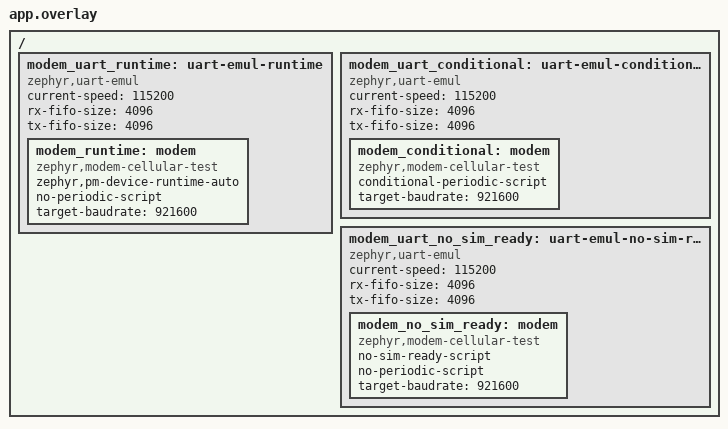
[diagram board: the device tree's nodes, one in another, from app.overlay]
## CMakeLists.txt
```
# Copyright (c) 2026 Embeint Inc
# SPDX-License-Identifier: Apache-2.0

cmake_minimum_required(VERSION 3.28.0)
# The test driver binding is shared with the original driver's tests
list(APPEND DTS_ROOT ${CMAKE_CURRENT_SOURCE_DIR}/../cellular_common)
find_package(Zephyr REQUIRED HINTS $ENV{ZEPHYR_BASE})
project(modem_cellular_v2_test)

set(common ${CMAKE_CURRENT_SOURCE_DIR}/../cellular_common)
target_sources(app PRIVATE
  ${common}/driver/modem_cellular_test.c
  ${common}/src/stubs.c
  ${common}/src/test_helpers.c
  src/apn.c
  src/board_init.c
  src/core.c
  src/gpio.c
  src/lte_rf.c
  src/modem_info.c
  src/periodic.c
  src/ppp.c
  src/registration.c
  src/script_errors.c
  src/sim.c
  src/suspend.c
)
target_include_directories(app PRIVATE
  ${common}/driver
  ${common}/src
  ${ZEPHYR_BASE}/subsys/modem
)
```

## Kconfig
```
# Copyright (c) 2026 Embeint Inc
# SPDX-License-Identifier: Apache-2.0

rsource "../cellular_common/Kconfig"

source "Kconfig.zephyr"
```

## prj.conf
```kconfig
# Copyright (c) 2026 Embeint Inc
# SPDX-License-Identifier: Apache-2.0

CONFIG_ZTEST=y

CONFIG_SERIAL=y
CONFIG_EMUL=y
CONFIG_UART_EMUL=y
CONFIG_GPIO=y

CONFIG_MODEM=y
CONFIG_MODEM_MODULES=y
CONFIG_MODEM_CELLULAR=y
CONFIG_MODEM_CELLULAR_V2=y
CONFIG_MODEM_CELLULAR_HW_DEPENDENCIES=n
CONFIG_MODEM_CHAT=y
CONFIG_MODEM_PIPELINK=y

CONFIG_NETWORKING=y
CONFIG_NET_L2_PPP=y
CONFIG_NET_MGMT=y
CONFIG_NET_MGMT_EVENT=y
CONFIG_PM_DEVICE=y
CONFIG_PM_DEVICE_RUNTIME=y
# The PPP L2 reports the link dead, as with the hardware dependencies
CONFIG_NET_L2_PPP_MGMT=y
# The PPP device reports why the modem failed
CONFIG_NET_MGMT_EVENT_INFO=y

CONFIG_ETH_NATIVE_TAP=n

CONFIG_LOG=y
CONFIG_LOG_MODE_IMMEDIATE=y
CONFIG_MODEM_LOG_LEVEL_INF=y

CONFIG_MODEM_CELLULAR_APN=""
CONFIG_MODEM_CELLULAR_RECOVERY_BACKOFF_MS=100
CONFIG_MODEM_CELLULAR_MAX_RECOVERIES=3
CONFIG_MODEM_CELLULAR_PERIODIC_SCRIPT_MS=500
CONFIG_MODEM_CELLULAR_SIM_TIMEOUT_MS=1000

CONFIG_MAIN_STACK_SIZE=4096
CONFIG_SYSTEM_WORKQUEUE_STACK_SIZE=4096
CONFIG_ZTEST_STACK_SIZE=4096
```

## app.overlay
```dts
/*
 * Copyright (c) 2026 Embeint Inc
 *
 * SPDX-License-Identifier: Apache-2.0
 */

#include "../cellular_common/modems.dtsi"

/* Modems only the MODEM_CELLULAR_V2 suites use */
/ {
	modem_uart_runtime: uart-emul-runtime {
		compatible = "zephyr,uart-emul";
		current-speed = <115200>;
		rx-fifo-size = <4096>;
		tx-fifo-size = <4096>;
		status = "okay";

		/* Only powered while something holds a runtime PM reference on it */
		modem_runtime: modem {
			compatible = "zephyr,modem-cellular-test";
			zephyr,pm-device-runtime-auto;
			/* Keeps the PPP tests to the commands they drive */
			no-periodic-script;
			target-baudrate = <921600>;
			status = "okay";
		};
	};

	modem_uart_conditional: uart-emul-conditional {
		compatible = "zephyr,uart-emul";
		current-speed = <115200>;
		rx-fifo-size = <4096>;
		tx-fifo-size = <4096>;
		status = "okay";

		modem_conditional: modem {
			compatible = "zephyr,modem-cellular-test";
			conditional-periodic-script;
			target-baudrate = <921600>;
			status = "okay";
		};
	};

	modem_uart_no_sim_ready: uart-emul-no-sim-ready {
		compatible = "zephyr,uart-emul";
		current-speed = <115200>;
		rx-fifo-size = <4096>;
		tx-fifo-size = <4096>;
		status = "okay";

		modem_no_sim_ready: modem {
			compatible = "zephyr,modem-cellular-test";
			no-sim-ready-script;
			no-periodic-script;
			target-baudrate = <921600>;
			status = "okay";
		};
	};
};
```

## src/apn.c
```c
/*
 * Copyright (c) 2026 Embeint Inc
 *
 * SPDX-License-Identifier: Apache-2.0
 */

/*
 * MODEM_CELLULAR_V2 configures the data context with the APN before each LTE RF enable, and
 * rejects LTE RF requests while no APN is available.
 */

#include "test_helpers.h"

#include <zephyr/device.h>
#include <zephyr/drivers/cellular.h>
#include <zephyr/drivers/modem/modem_cellular.h>
#include <modem_cellular_test.h>
#include <zephyr/ztest.h>

BUILD_ASSERT(IS_ENABLED(CONFIG_MODEM_CELLULAR_V2));

#define OTHER_APN     "other"
#define OTHER_APN_CMD "AT+CGDCONT=1,\"IP\",\"" OTHER_APN "\""

/* Without a periodic script, so that only the commands under test are sent */
static const struct device *const modem = DEVICE_DT_GET(DT_NODELABEL(modem_no_periodic));
static const struct device *const modem_default_pdp =
	DEVICE_DT_GET(DT_NODELABEL(modem_default_pdp));

static void boot_to_ready(const struct device *dev)
{
	modem_restart(dev);
	advance_to(dev, BOOT_AT_READY);
}

/* Answer @p cmd with OK, or ERROR unless @p success, and check the driver read it */
static void answer(const char *cmd, bool success)
{
	expect_line(TEST_BACKEND_PIPE_DLCI1, cmd);
	if (success) {
		ok(TEST_BACKEND_PIPE_DLCI1);
	} else {
		respond_error(TEST_BACKEND_PIPE_DLCI1);
	}
	expect_read(TEST_BACKEND_PIPE_DLCI1);
}

ZTEST(modem_cellular_v2_apn, test_request_rejected_without_apn)
{
	boot_to_ready(modem);

	zassert_equal(-ENODATA, modem_cellular_lte_rf_request(modem));
	expect_no_line(K_MSEC(100));
	/* A rejected request is not held */
	zassert_equal(-EALREADY, modem_cellular_lte_rf_release(modem));
}

/* An APN set once a request was rejected lets the next one through */
ZTEST(modem_cellular_v2_apn, test_request_after_apn_set)
{
	boot_to_ready(modem);
	zassert_equal(-ENODATA, modem_cellular_lte_rf_request(modem));

	zassert_ok(cellular_set_apn(modem, TEST_APN));
	zassert_ok(modem_cellular_lte_rf_request(modem));
	answer(TEST_APN_CMD, true);
	answer(MODEM_CELLULAR_TEST_LTE_RF_ENABLE_CMD, true);
	expect_no_line(K_MSEC(100));
}

/* An empty APN counts as set, and is configured for the network to select the default APN */
ZTEST(modem_cellular_v2_apn, test_empty_apn)
{
	boot_to_ready(modem);
	zassert_equal(-ENODATA, modem_cellular_lte_rf_request(modem));

	zassert_ok(cellular_set_apn(modem, ""));
	zassert_equal(-EALREADY, cellular_set_apn(modem, ""));
	zassert_ok(modem_cellular_lte_rf_request(modem));
	answer("AT+CGDCONT=1,\"IP\",\"\"", true);
	answer(MODEM_CELLULAR_TEST_LTE_RF_ENABLE_CMD, true);
	expect_no_line(K_MSEC(100));
}

ZTEST(modem_cellular_v2_apn, test_set_apn_validated)
{
	char too_long[MODEM_CELLULAR_DATA_APN_LEN + 1];

	memset(too_long, 'a', sizeof(too_long) - 1);
	too_long[sizeof(too_long) - 1] = '\0';

	zassert_equal(-EINVAL, cellular_set_apn(modem, NULL));
	zassert_equal(-EINVAL, cellular_set_apn(modem, too_long));
	zassert_ok(cellular_set_apn(modem, TEST_APN));
	zassert_equal(-EALREADY, cellular_set_apn(modem, TEST_APN));
}

/* The APN cannot change under a held request, and the new one is used on the next enable */
ZTEST(modem_cellular_v2_apn, test_change_while_requested)
{
	boot_to_ready(modem);
	zassert_ok(cellular_set_apn(modem, TEST_APN));
	zassert_ok(modem_cellular_lte_rf_request(modem));
	answer(TEST_APN_CMD, true);
	answer(MODEM_CELLULAR_TEST_LTE_RF_ENABLE_CMD, true);

	zassert_equal(-EBUSY, cellular_set_apn(modem, OTHER_APN));

	zassert_ok(modem_cellular_lte_rf_release(modem));
	answer(MODEM_CELLULAR_TEST_LTE_RF_DISABLE_CMD, true);
	zassert_ok(cellular_set_apn(modem, OTHER_APN));

	zassert_ok(modem_cellular_lte_rf_request(modem));
	answer(OTHER_APN_CMD, true);
	answer(MODEM_CELLULAR_TEST_LTE_RF_ENABLE_CMD, true);
}

/* Release, set the APN and request again before the driver gets to run */
static void change_apn_at_once(void)
{
	zassert_ok(modem_cellular_lte_rf_release(modem));
	zassert_ok(cellular_set_apn(modem, OTHER_APN));
	zassert_ok(modem_cellular_lte_rf_request(modem));
}

/* An APN changed between a release and the next request is configured, however quickly the
 * request follows
 */
ZTEST(modem_cellular_v2_apn, test_change_between_release_and_request)
{
	boot_to_ready(modem);
	zassert_ok(cellular_set_apn(modem, TEST_APN));
	zassert_ok(modem_cellular_lte_rf_request(modem));
	answer(TEST_APN_CMD, true);
	answer(MODEM_CELLULAR_TEST_LTE_RF_ENABLE_CMD, true);

	change_apn_at_once();
	answer(MODEM_CELLULAR_TEST_LTE_RF_DISABLE_CMD, true);
	answer(OTHER_APN_CMD, true);
	answer(MODEM_CELLULAR_TEST_LTE_RF_ENABLE_CMD, true);
	expect_no_line(K_MSEC(100));
}

/* As test_change_between_release_and_request, while the old APN is being configured */
ZTEST(modem_cellular_v2_apn, test_change_during_configuration)
{
	boot_to_ready(modem);
	zassert_ok(cellular_set_apn(modem, TEST_APN));
	zassert_ok(modem_cellular_lte_rf_request(modem));
	expect_line(TEST_BACKEND_PIPE_DLCI1, TEST_APN_CMD);

	change_apn_at_once();
	ok(TEST_BACKEND_PIPE_DLCI1);
	answer(OTHER_APN_CMD, true);
	answer(MODEM_CELLULAR_TEST_LTE_RF_ENABLE_CMD, true);
	expect_no_line(K_MSEC(100));
}

/* As test_change_between_release_and_request, while the LTE RF is being enabled */
ZTEST(modem_cellular_v2_apn, test_change_during_enable)
{
	boot_to_ready(modem);
	zassert_ok(cellular_set_apn(modem, TEST_APN));
	zassert_ok(modem_cellular_lte_rf_request(modem));
	answer(TEST_APN_CMD, true);
	expect_line(TEST_BACKEND_PIPE_DLCI1, MODEM_CELLULAR_TEST_LTE_RF_ENABLE_CMD);

	change_apn_at_once();
	ok(TEST_BACKEND_PIPE_DLCI1);
	answer(MODEM_CELLULAR_TEST_LTE_RF_DISABLE_CMD, true);
	answer(OTHER_APN_CMD, true);
	answer(MODEM_CELLULAR_TEST_LTE_RF_ENABLE_CMD, true);
	expect_no_line(K_MSEC(100));
}

/* A failed configuration is retried after the LTE RF retry interval, the LTE RF staying off */
ZTEST(modem_cellular_v2_apn, test_failure_retried)
{
	int64_t start;

	boot_to_ready(modem);
	zassert_ok(cellular_set_apn(modem, TEST_APN));
	zassert_ok(modem_cellular_lte_rf_request(modem));
	expect_line(TEST_BACKEND_PIPE_DLCI1, TEST_APN_CMD);

	start = k_uptime_get();
	respond_error(TEST_BACKEND_PIPE_DLCI1);
	expect_no_line(K_MSEC(CONFIG_MODEM_CELLULAR_LTE_RF_RETRY_MS / 2));
	answer(TEST_APN_CMD, true);
	zassert_true(k_uptime_delta(&start) >= CONFIG_MODEM_CELLULAR_LTE_RF_RETRY_MS,
		     "retried before the LTE RF retry interval");
	answer(MODEM_CELLULAR_TEST_LTE_RF_ENABLE_CMD, true);
}

ZTEST(modem_cellular_v2_apn, test_failure_released)
{
	boot_to_ready(modem);
	zassert_ok(cellular_set_apn(modem, TEST_APN));
	zassert_ok(modem_cellular_lte_rf_request(modem));
	answer(TEST_APN_CMD, false);

	zassert_ok(modem_cellular_lte_rf_release(modem));
	expect_no_line(K_MSEC(CONFIG_MODEM_CELLULAR_LTE_RF_RETRY_MS * 2));
}

/* Releasing while the APN is configured leaves the LTE RF off */
ZTEST(modem_cellular_v2_apn, test_released_during_configuration)
{
	boot_to_ready(modem);
	zassert_ok(cellular_set_apn(modem, TEST_APN));
	zassert_ok(modem_cellular_lte_rf_request(modem));
	expect_line(TEST_BACKEND_PIPE_DLCI1, TEST_APN_CMD);

	zassert_ok(modem_cellular_lte_rf_release(modem));
	ok(TEST_BACKEND_PIPE_DLCI1);
	expect_read(TEST_BACKEND_PIPE_DLCI1);
	expect_no_line(K_MSEC(100));
}

/* The APN is configured again on each enable, as the modem may have lost it */
ZTEST(modem_cellular_v2_apn, test_configured_on_each_enable)
{
	boot_to_ready(modem);
	zassert_ok(cellular_set_apn(modem, TEST_APN));
	zassert_ok(modem_cellular_lte_rf_request(modem));
	answer(TEST_APN_CMD, true);
	answer(MODEM_CELLULAR_TEST_LTE_RF_ENABLE_CMD, true);
	suspend_with_lte_rf_and_shutdown(modem);

	zassert_ok(modem_cellular_pm_action(modem, PM_DEVICE_ACTION_RESUME), "resume failed");
	advance_to(modem, BOOT_AT_READY);
	answer(TEST_APN_CMD, true);
	answer(MODEM_CELLULAR_TEST_LTE_RF_ENABLE_CMD, true);
}

/* The default PDP context is left to the modem, so no APN is needed or configured */
ZTEST(modem_cellular_v2_apn, test_default_pdp_context)
{
	boot_to_ready(modem_default_pdp);

	zassert_ok(modem_cellular_lte_rf_request(modem_default_pdp));
	answer(MODEM_CELLULAR_TEST_LTE_RF_ENABLE_CMD, true);
	expect_no_line(K_MSEC(100));
}

ZTEST_SUITE(modem_cellular_v2_apn, NULL, modem_test_setup, modem_test_before, modem_test_after,
	    NULL);
```

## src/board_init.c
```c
/*
 * Copyright (c) 2026 Embeint Inc
 *
 * SPDX-License-Identifier: Apache-2.0
 */

#include "test_helpers.h"

#include <zephyr/device.h>
#include <zephyr/drivers/cellular.h>
#include <zephyr/drivers/modem/modem_cellular.h>
#include <modem_cellular_test.h>
#include <zephyr/modem/chat.h>
#include <zephyr/ztest.h>

#define BOARD_INIT_CMD_1 "AT+BOARDINIT=1"
#define BOARD_INIT_CMD_2 "AT+BOARDINIT=2"

static const struct device *const modem_board_init =
	DEVICE_DT_GET(DT_NODELABEL(modem_board_init));

MODEM_CHAT_MATCH_DEFINE(board_init_ok_match, "OK", "", NULL);
MODEM_CHAT_MATCHES_DEFINE(board_init_abort_matches, MODEM_CHAT_MATCH("ERROR", "", NULL));
MODEM_CHAT_SCRIPT_CMDS_DEFINE(board_init_cmds,
			      MODEM_CHAT_SCRIPT_CMD_RESP(BOARD_INIT_CMD_1, board_init_ok_match),
			      MODEM_CHAT_SCRIPT_CMD_RESP(BOARD_INIT_CMD_2, board_init_ok_match));
/* The driver replaces the callback with its own */
MODEM_CHAT_SCRIPT_DEFINE(board_init_script, board_init_cmds, board_init_abort_matches, NULL, 1);

MODEM_CELLULAR_BOARD_INIT_DEFINE(DT_NODELABEL(modem_board_init), &board_init_script);

/* Boot until the board init script is about to start, after the DLCI setup and SIM check */
static void boot_to_board_init(void)
{
	modem_restart(modem_board_init);
	advance_to(modem_board_init, BOOT_AT_READY);
}

/* Answer the whole board init script */
static void run_board_init(void)
{
	expect_line(TEST_BACKEND_PIPE_DLCI1, BOARD_INIT_CMD_1);
	ok(TEST_BACKEND_PIPE_DLCI1);
	expect_line(TEST_BACKEND_PIPE_DLCI1, BOARD_INIT_CMD_2);
	ok(TEST_BACKEND_PIPE_DLCI1);
}

/* With the script done, the driver moves on to the APN */
static void expect_apn(void)
{
	expect_read(TEST_BACKEND_PIPE_DLCI1);
	expect_no_line(K_MSEC(100));
	zassert_ok(cellular_set_apn(modem_board_init, TEST_APN));
	zassert_ok(modem_cellular_lte_rf_request(modem_board_init));
	expect_line(TEST_BACKEND_PIPE_DLCI1, TEST_APN_CMD);
}

/* The script runs on DLCI1 once the SIM is checked, before the APN is configured */
ZTEST(modem_cellular_board_init, test_runs_before_apn)
{
	boot_to_board_init();
	run_board_init();
	expect_apn();
}

static K_SEM_DEFINE(modem_ready, 0, K_SEM_MAX_LIMIT);

static void modem_ready_handler(const struct device *dev, enum cellular_event event,
				const void *payload, void *user_data)
{
	ARG_UNUSED(dev);
	ARG_UNUSED(event);
	ARG_UNUSED(payload);
	ARG_UNUSED(user_data);

	k_sem_give(&modem_ready);
}

/* The modem is only reported ready once the script has run */
ZTEST(modem_cellular_board_init, test_ready_after_script)
{
	k_sem_reset(&modem_ready);
	zassert_ok(cellular_set_callback(modem_board_init, CELLULAR_EVENT_MODEM_READY,
					 modem_ready_handler, NULL));

	boot_to_board_init();
	expect_line(TEST_BACKEND_PIPE_DLCI1, BOARD_INIT_CMD_1);
	ok(TEST_BACKEND_PIPE_DLCI1);
	expect_line(TEST_BACKEND_PIPE_DLCI1, BOARD_INIT_CMD_2);
	zassert_equal(0, k_sem_count_get(&modem_ready), "ready reported during the script");

	ok(TEST_BACKEND_PIPE_DLCI1);
	zassert_ok(k_sem_take(&modem_ready, K_SECONDS(1)), "ready not reported");

	zassert_ok(cellular_set_callback(modem_board_init, 0, NULL, NULL));
}

/* A failed script is run again from the start after the periodic interval */
ZTEST(modem_cellular_board_init, test_retried)
{
	int64_t start;

	boot_to_board_init();
	expect_line(TEST_BACKEND_PIPE_DLCI1, BOARD_INIT_CMD_1);
	ok(TEST_BACKEND_PIPE_DLCI1);
	expect_line(TEST_BACKEND_PIPE_DLCI1, BOARD_INIT_CMD_2);

	start = k_uptime_get();
	respond_error(TEST_BACKEND_PIPE_DLCI1);
	expect_no_line(K_MSEC(CONFIG_MODEM_CELLULAR_PERIODIC_SCRIPT_MS / 2));
	run_board_init();
	zassert_true(k_uptime_delta(&start) >= CONFIG_MODEM_CELLULAR_PERIODIC_SCRIPT_MS,
		     "retried before the periodic interval");
	expect_apn();
}

static atomic_t modem_failed;

static void modem_failed_handler(const struct device *dev, enum cellular_event event,
				 const void *payload, void *user_data)
{
	ARG_UNUSED(dev);
	ARG_UNUSED(event);
	ARG_UNUSED(payload);
	ARG_UNUSED(user_data);

	atomic_inc(&modem_failed);
}

/* Spending the failure budget powers the modem down */
ZTEST(modem_cellular_board_init, test_failures_shut_down)
{
	boot_to_board_init();
	atomic_clear(&modem_failed);
	zassert_ok(cellular_set_callback(modem_board_init, CELLULAR_EVENT_MODEM_FAILED,
					 modem_failed_handler, NULL));
	for (int i = 0; i < CONFIG_MODEM_CELLULAR_MAX_SCRIPT_FAILURES; i++) {
		expect_line(TEST_BACKEND_PIPE_DLCI1, BOARD_INIT_CMD_1);
		respond_error(TEST_BACKEND_PIPE_DLCI1);
	}

	expect_line(TEST_BACKEND_PIPE_UART, MODEM_CELLULAR_TEST_SHUTDOWN_CMD);
	ok(TEST_BACKEND_PIPE_UART);
	expect_state(modem_board_init, TEST_BACKEND_STATE_OFF);
	expect_no_line(K_MSEC(CONFIG_MODEM_CELLULAR_PERIODIC_SCRIPT_MS * 2));
	zassert_equal(1, atomic_get(&modem_failed), "modem failure not reported");
}

/* Failures before a suspend do not count against the script after the resume */
ZTEST(modem_cellular_board_init, test_failures_forgotten_on_resume)
{
	boot_to_board_init();
	expect_line(TEST_BACKEND_PIPE_DLCI1, BOARD_INIT_CMD_1);
	respond_error(TEST_BACKEND_PIPE_DLCI1);
	suspend_and_shutdown(modem_board_init);

	zassert_ok(modem_cellular_pm_action(modem_board_init, PM_DEVICE_ACTION_RESUME));
	advance_to(modem_board_init, BOOT_AT_READY);
	for (int i = 0; i < CONFIG_MODEM_CELLULAR_MAX_SCRIPT_FAILURES - 1; i++) {
		expect_line(TEST_BACKEND_PIPE_DLCI1, BOARD_INIT_CMD_1);
		respond_error(TEST_BACKEND_PIPE_DLCI1);
	}
	run_board_init();
	expect_apn();
}

ZTEST(modem_cellular_board_init, test_suspend)
{
	boot_to_board_init();
	expect_line(TEST_BACKEND_PIPE_DLCI1, BOARD_INIT_CMD_1);
	suspend_and_shutdown(modem_board_init);
}

ZTEST_SUITE(modem_cellular_board_init, NULL, modem_test_setup, modem_test_before,
	    modem_test_after, NULL);
```

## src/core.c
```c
/*
 * Copyright (c) 2026 Embeint Inc
 *
 * SPDX-License-Identifier: Apache-2.0
 */

/*
 * MODEM_CELLULAR_V2 brings the modem up until the CMUX connects and it has set up the AT
 * command channel on DLCI1, and no further. The PPP channel on DLCI2 is then handed out
 * through a pipelink, as are the user pipes.
 */

#include "test_helpers.h"

#include <zephyr/device.h>
#include <zephyr/drivers/cellular.h>
#include <zephyr/drivers/gpio/gpio_emul.h>
#include <zephyr/drivers/modem/modem_cellular.h>
#include <modem_cellular_test.h>
#include <modem_workqueue.h>
#include <zephyr/modem/pipe.h>
#include <zephyr/modem/pipelink.h>
#include <zephyr/ztest.h>

#include <string.h>

BUILD_ASSERT(IS_ENABLED(CONFIG_MODEM_CELLULAR_V2));

#define TARGET_BAUDRATE          DT_PROP(DT_ALIAS(modem), target_baudrate)
#define BAUDRATE_UPDATE_DELAY_MS DT_PROP(DT_ALIAS(modem), baudrate_update_delay_ms)

static const struct device *const modem = DEVICE_DT_GET(DT_ALIAS(modem));
static const struct device *const modem_slow = DEVICE_DT_GET(DT_NODELABEL(modem_slow));
static const struct device *const modem_no_power = DEVICE_DT_GET(DT_NODELABEL(modem_no_power));
static const struct device *const modem_no_shutdown =
	DEVICE_DT_GET(DT_NODELABEL(modem_no_shutdown));
static const struct device *const modem_no_dlci_setup =
	DEVICE_DT_GET(DT_NODELABEL(modem_no_dlci_setup));

MODEM_PIPELINK_DT_DECLARE(DT_ALIAS(modem), MODEM_CELLULAR_PIPELINK_PPP);
MODEM_PIPELINK_DT_DECLARE(DT_ALIAS(modem), user_pipe_0);
MODEM_PIPELINK_DT_DECLARE(DT_ALIAS(modem), user_pipe_1);
MODEM_PIPELINK_DT_DECLARE(DT_NODELABEL(modem_no_dlci_setup), MODEM_CELLULAR_PIPELINK_PPP);

/* Every pipelink of the modem, and the DLCI it carries */
static const struct {
	struct modem_pipelink *link;
	enum test_backend_pipe_id pipe;
} pipelinks[] = {
	{MODEM_PIPELINK_DT_GET(DT_ALIAS(modem), MODEM_CELLULAR_PIPELINK_PPP),
	 TEST_BACKEND_PIPE_DLCI2},
	{MODEM_PIPELINK_DT_GET(DT_ALIAS(modem), user_pipe_0), TEST_BACKEND_PIPE_USER3},
	{MODEM_PIPELINK_DT_GET(DT_ALIAS(modem), user_pipe_1), TEST_BACKEND_PIPE_USER4},
};

static void expect_pipelinks_connected(bool connected)
{
	for (size_t i = 0; i < ARRAY_SIZE(pipelinks); i++) {
		zassert_equal(connected, modem_pipelink_is_connected(pipelinks[i].link),
			      "pipelink %zu connected is %d", i, !connected);
	}
}

/* The driver keeps the AT command channel, and brings nothing else up */
ZTEST(modem_cellular_v2_core, test_stops_when_at_ready)
{
	modem_restart(modem);
	advance_to(modem, BOOT_AT_READY);
	expect_pipelinks_connected(true);
	zassert_true(test_backend_pipe_is_open(TEST_BACKEND_PIPE_DLCI1), "DLCI1 not opened");
	zassert_false(test_backend_pipe_is_open(TEST_BACKEND_PIPE_DLCI2), "DLCI2 opened");

	/* The driver chat reads the AT command channel */
	registered(TEST_BACKEND_PIPE_DLCI1);
	expect_read(TEST_BACKEND_PIPE_DLCI1);

	/* Nothing until the periodic script is due */
	expect_no_line(K_MSEC(CONFIG_MODEM_CELLULAR_PERIODIC_SCRIPT_MS / 2));
	zassert_equal(TEST_BACKEND_STATE_CMUX, test_backend_state(modem));
}

/* The other channels are only handed out once DLCI1 is set up and the SIM checked */
ZTEST(modem_cellular_v2_core, test_pipelinks_wait_for_dlci_setup)
{
	modem_restart(modem);
	advance_to(modem, BOOT_CMUX_PENDING);
	expect_pipelinks_connected(false);

	test_backend_cmux_connect_finish(true);
	expect_line(TEST_BACKEND_PIPE_DLCI1, MODEM_CELLULAR_TEST_DLCI_SETUP_CMD);
	expect_pipelinks_connected(false);

	ok(TEST_BACKEND_PIPE_DLCI1);
	answer_reports();
	expect_line(TEST_BACKEND_PIPE_DLCI1, TEST_CPIN_CMD);
	expect_pipelinks_connected(false);

	respond_cpin("READY");
	expect_line(TEST_BACKEND_PIPE_DLCI1, MODEM_CELLULAR_TEST_SIM_READY_CMD);
	expect_pipelinks_connected(false);

	ok(TEST_BACKEND_PIPE_DLCI1);
	expect_read(TEST_BACKEND_PIPE_DLCI1);
	flush_driver_events();
	expect_pipelinks_connected(true);
}

/* A failed DLCI setup is not critical, the channel still takes commands */
ZTEST(modem_cellular_v2_core, test_dlci_setup_failure)
{
	modem_restart(modem);
	advance_to(modem, BOOT_DLCI1_SETUP);

	respond_error(TEST_BACKEND_PIPE_DLCI1);
	answer_reports();
	expect_line(TEST_BACKEND_PIPE_DLCI1, TEST_CPIN_CMD);
	respond_cpin("READY");
	expect_line(TEST_BACKEND_PIPE_DLCI1, MODEM_CELLULAR_TEST_SIM_READY_CMD);
	ok(TEST_BACKEND_PIPE_DLCI1);
	expect_read(TEST_BACKEND_PIPE_DLCI1);
	flush_driver_events();
	expect_pipelinks_connected(true);
	expect_no_line(K_MSEC(100));
}

/* Reports the modem cannot enable are logged, and the modem brought up regardless */
ZTEST(modem_cellular_v2_core, test_reports_failure)
{
	modem_restart(modem);
	advance_to(modem, BOOT_REPORTS);

	respond_error(TEST_BACKEND_PIPE_DLCI1);
	expect_line(TEST_BACKEND_PIPE_DLCI1, TEST_CEREG_CMD);
	respond_error(TEST_BACKEND_PIPE_DLCI1);
	expect_line(TEST_BACKEND_PIPE_DLCI1, TEST_CGEREP_CMD);
	test_backend_respond(TEST_BACKEND_PIPE_DLCI1, "+CME ERROR: 4\r");
	expect_line(TEST_BACKEND_PIPE_DLCI1, TEST_CPIN_CMD);
	respond_cpin("READY");
	expect_line(TEST_BACKEND_PIPE_DLCI1, MODEM_CELLULAR_TEST_SIM_READY_CMD);
	ok(TEST_BACKEND_PIPE_DLCI1);
	expect_read(TEST_BACKEND_PIPE_DLCI1);
	flush_driver_events();
	expect_pipelinks_connected(true);
}

/* Without a DLCI setup script the reports are enabled as soon as DLCI1 opens */
ZTEST(modem_cellular_v2_core, test_no_dlci_setup_script)
{
	struct modem_pipelink *ppp = MODEM_PIPELINK_DT_GET(DT_NODELABEL(modem_no_dlci_setup),
							   MODEM_CELLULAR_PIPELINK_PPP);

	modem_restart(modem_no_dlci_setup);
	advance_to(modem_no_dlci_setup, BOOT_CMUX_CONNECTED);
	answer_reports();
	expect_line(TEST_BACKEND_PIPE_DLCI1, TEST_CPIN_CMD);
	respond_cpin("READY");
	expect_line(TEST_BACKEND_PIPE_DLCI1, MODEM_CELLULAR_TEST_SIM_READY_CMD);
	ok(TEST_BACKEND_PIPE_DLCI1);
	expect_read(TEST_BACKEND_PIPE_DLCI1);
	flush_driver_events();
	zassert_true(modem_pipelink_is_connected(ppp), "PPP pipelink not connected");
	zassert_true(test_backend_pipe_is_open(TEST_BACKEND_PIPE_DLCI1), "DLCI1 not opened");
	expect_no_line(K_MSEC(100));
}

/* Suspending before DLCI1 is set up never hands out the other channels */
ZTEST(modem_cellular_v2_core, test_suspend_during_dlci_setup)
{
	modem_restart(modem);
	advance_to(modem, BOOT_DLCI1_SETUP);

	suspend_and_shutdown(modem);
	expect_pipelinks_connected(false);
}

/* Pipelinks each carry their own DLCI */
ZTEST(modem_cellular_v2_core, test_pipelinks)
{
	static const char cmd[] = "AT+USER\r";

	modem_restart(modem);
	advance_to(modem, BOOT_AT_READY);
	for (size_t i = 0; i < ARRAY_SIZE(pipelinks); i++) {
		struct modem_pipe *pipe = modem_pipelink_get_pipe(pipelinks[i].link);

		zassert_ok(modem_pipe_open(pipe, K_SECONDS(2)));
		zassert_true(test_backend_pipe_is_open(pipelinks[i].pipe));
		zassert_equal(strlen(cmd),
			      modem_pipe_transmit(pipe, (const uint8_t *)cmd, strlen(cmd)));
		expect_line(pipelinks[i].pipe, "AT+USER");
	}

	suspend_and_shutdown(modem);
	expect_pipelinks_connected(false);
}

/* Halting the driver disconnects the pipelinks, as powering down does */
ZTEST(modem_cellular_v2_core, test_pipelinks_halt)
{
	modem_restart(modem);
	advance_to(modem, BOOT_AT_READY);
	expect_pipelinks_connected(true);

	modem_cellular_ztest_halt(modem);
	expect_pipelinks_connected(false);
}

/* The modem powers up at its default baudrate, so the UART is restored first */
ZTEST(modem_cellular_v2_core, test_suspend_and_resume)
{
	modem_restart(modem);
	advance_to(modem, BOOT_AT_READY);
	zassert_equal(TARGET_BAUDRATE, uart_baudrate(modem),
		      "UART baudrate was not switched");

	suspend_and_shutdown(modem);

	zassert_ok(modem_cellular_pm_action(modem, PM_DEVICE_ACTION_RESUME), "resume failed");
	expect_line(TEST_BACKEND_PIPE_UART, MODEM_CELLULAR_TEST_SET_BAUDRATE_CMD);
	zassert_equal(modem_power_up_baudrate(modem), uart_baudrate(modem),
		      "UART baudrate was not restored on power up");
	ok(TEST_BACKEND_PIPE_UART);

	expect_line(TEST_BACKEND_PIPE_UART, MODEM_CELLULAR_TEST_INIT_CMD);
	zassert_equal(TARGET_BAUDRATE, uart_baudrate(modem),
		      "UART baudrate was not switched");
	ok(TEST_BACKEND_PIPE_UART);
	expect_line(TEST_BACKEND_PIPE_DLCI1, MODEM_CELLULAR_TEST_DLCI_SETUP_CMD);
}

static K_SEM_DEFINE(modem_ready, 0, K_SEM_MAX_LIMIT);

static void modem_ready_handler(const struct device *dev, enum cellular_event event,
				const void *payload, void *user_data)
{
	ARG_UNUSED(dev);
	ARG_UNUSED(event);
	ARG_UNUSED(payload);
	ARG_UNUSED(user_data);

	k_sem_give(&modem_ready);
}

/* Readiness is reported once per boot, and not on suspend */
ZTEST(modem_cellular_v2_core, test_ready_reported_each_boot)
{
	k_sem_reset(&modem_ready);
	zassert_ok(cellular_set_callback(modem, CELLULAR_EVENT_MODEM_READY, modem_ready_handler,
					 NULL));

	modem_restart(modem);
	advance_to(modem, BOOT_AT_READY);
	zassert_ok(k_sem_take(&modem_ready, K_SECONDS(1)), "ready not reported");

	suspend_and_shutdown(modem);
	zassert_equal(0, k_sem_count_get(&modem_ready), "ready reported on suspend");

	zassert_ok(modem_cellular_pm_action(modem, PM_DEVICE_ACTION_RESUME), "resume failed");
	advance_to(modem, BOOT_AT_READY);
	zassert_ok(k_sem_take(&modem_ready, K_SECONDS(1)), "ready not reported on resume");
	zassert_equal(0, k_sem_count_get(&modem_ready), "ready reported more than once");

	zassert_ok(cellular_set_callback(modem, 0, NULL, NULL));
}

/*
 * Without a reset or power key, recovery boots the modem again as it is, at its power up
 * baudrate, until the recovery attempts are spent.
 */
ZTEST(modem_cellular_v2_core, test_recovery_without_gpios)
{
	modem_restart(modem_no_power);
	advance_to(modem_no_power, BOOT_SET_BAUDRATE);
	ok(TEST_BACKEND_PIPE_UART);

	for (int i = 0; i < CONFIG_MODEM_CELLULAR_MAX_RECOVERIES; i++) {
		expect_line(TEST_BACKEND_PIPE_UART, MODEM_CELLULAR_TEST_INIT_CMD);
		respond_error(TEST_BACKEND_PIPE_UART);
		expect_line(TEST_BACKEND_PIPE_UART, MODEM_CELLULAR_TEST_SET_BAUDRATE_CMD);
		zassert_equal(modem_power_up_baudrate(modem_no_power),
			      uart_baudrate(modem_no_power),
			      "UART baudrate was not restored for the retry");
		ok(TEST_BACKEND_PIPE_UART);
	}

	/* Spent, so powered down rather than retried */
	expect_line(TEST_BACKEND_PIPE_UART, MODEM_CELLULAR_TEST_INIT_CMD);
	respond_error(TEST_BACKEND_PIPE_UART);
	expect_state(modem_no_power, TEST_BACKEND_STATE_OFF);
	expect_no_line(K_MSEC(CONFIG_MODEM_CELLULAR_RECOVERY_BACKOFF_MS *
			      (CONFIG_MODEM_CELLULAR_MAX_RECOVERIES + 1)));
}

ZTEST(modem_cellular_v2_core, test_uart_backend_init_failure)
{
	modem_reset_state(modem);
	test_backend_uart_init_fail_once();
	zassert_equal(-EIO, modem_cellular_init(modem));

	/* A later initialization can still succeed. */
	modem_restart(modem);
	advance_to(modem, BOOT_SET_BAUDRATE);
}

ZTEST(modem_cellular_v2_core, test_uart_open_failure_recovers)
{
	modem_restart(modem);
	advance_to(modem, BOOT_SET_BAUDRATE);
	test_backend_pipe_fail_next_open(TEST_BACKEND_PIPE_UART);
	ok(TEST_BACKEND_PIPE_UART);

	/* The failed init-script open enters recovery and starts boot again. */
	expect_line(TEST_BACKEND_PIPE_UART, MODEM_CELLULAR_TEST_SET_BAUDRATE_CMD);
}

ZTEST(modem_cellular_v2_core, test_uart_close_failure_recovers)
{
	modem_restart(modem);
	advance_to(modem, BOOT_INIT);
	test_backend_pipe_fail_next_close(TEST_BACKEND_PIPE_UART);
	ok(TEST_BACKEND_PIPE_UART);

	/* The failed close after init enters recovery and starts boot again. */
	expect_line(TEST_BACKEND_PIPE_UART, MODEM_CELLULAR_TEST_SET_BAUDRATE_CMD);
}

ZTEST(modem_cellular_v2_core, test_dlci1_open_failure_recovers)
{
	modem_restart(modem);
	advance_to(modem, BOOT_CMUX_PENDING);
	test_backend_pipe_fail_next_open(TEST_BACKEND_PIPE_DLCI1);
	test_backend_cmux_connect_finish(true);

	/* The failed command-channel open enters recovery and starts boot again. */
	expect_line(TEST_BACKEND_PIPE_UART, MODEM_CELLULAR_TEST_SET_BAUDRATE_CMD);
}

ZTEST(modem_cellular_v2_core, test_dlci1_open_timeout_recovers)
{
	modem_restart(modem);
	advance_to(modem, BOOT_CMUX_PENDING);
	test_backend_pipe_close_next_open(TEST_BACKEND_PIPE_DLCI1);
	test_backend_cmux_connect_finish(true);

	/* The CMUX reports a closed pipe after its open retries are exhausted. */
	expect_line(TEST_BACKEND_PIPE_UART, MODEM_CELLULAR_TEST_SET_BAUDRATE_CMD);
}

/* A command-channel failure remains visible after the chat has attached to DLCI1. */
ZTEST(modem_cellular_v2_core, test_dlci1_close_after_attach_recovers)
{
	modem_restart(modem_no_dlci_setup);
	advance_to(modem_no_dlci_setup, BOOT_SIM);

	test_backend_pipe_disconnect(TEST_BACKEND_PIPE_DLCI1);

	/* Recovery restarts the modem instead of waiting for a future script failure. */
	expect_line(TEST_BACKEND_PIPE_UART, MODEM_CELLULAR_TEST_SET_BAUDRATE_CMD);
}

/* The init script waits for the UART to close and reopen at the new baudrate, however long the
 * close takes
 */
ZTEST(modem_cellular_v2_core, test_baudrate_waits_for_close)
{
	modem_restart(modem);
	advance_to(modem, BOOT_SET_BAUDRATE);
	test_backend_pipe_close_hold(TEST_BACKEND_PIPE_UART);
	ok(TEST_BACKEND_PIPE_UART);
	zassert_true(test_backend_pipe_wait_for_close(TEST_BACKEND_PIPE_UART, K_SECONDS(1)),
		     "UART not closed after the set baudrate script");

	expect_no_line(K_MSEC(BAUDRATE_UPDATE_DELAY_MS + 100));
	zassert_equal(modem_power_up_baudrate(modem), uart_baudrate(modem),
		      "baudrate changed before the UART closed");

	test_backend_pipe_close_finish(TEST_BACKEND_PIPE_UART);
	expect_line(TEST_BACKEND_PIPE_UART, MODEM_CELLULAR_TEST_INIT_CMD);
	zassert_equal(TARGET_BAUDRATE, uart_baudrate(modem),
		      "init script not run at the new baudrate");
}

static K_SEM_DEFINE(workqueue_release, 0, 1);

static void workqueue_block_handler(struct k_work *work)
{
	ARG_UNUSED(work);

	(void)k_sem_take(&workqueue_release, K_FOREVER);
}

/* An open that completes after the startup time ran out, with its event queued behind the
 * timeout, does not restart the script started once the UART is reopened
 */
ZTEST(modem_cellular_v2_core, test_late_uart_open_ignored)
{
	static struct k_work block;

	modem_reset_state(modem_slow);
	test_backend_pipe_open_hold(TEST_BACKEND_PIPE_UART);
	zassert_ok(modem_cellular_init(modem_slow));
	zassert_true(test_backend_pipe_wait_for_open(TEST_BACKEND_PIPE_UART, K_SECONDS(2)),
		     "UART never opened");

	/* Hold the driver until the startup time is out, then complete the open */
	k_sem_reset(&workqueue_release);
	k_work_init(&block, workqueue_block_handler);
	zassert_equal(1, modem_work_submit(&block));
	k_msleep(DT_PROP(DT_NODELABEL(modem_slow), startup_time_ms) * 2);
	test_backend_pipe_open_finish(TEST_BACKEND_PIPE_UART);
	k_sem_give(&workqueue_release);

	/* The reopened UART reports open at once, and the second report changes nothing */
	expect_line(TEST_BACKEND_PIPE_UART, MODEM_CELLULAR_TEST_SET_BAUDRATE_CMD);
	flush_driver_events();
	zassert_true(test_backend_pipe_is_open(TEST_BACKEND_PIPE_UART),
		     "set baudrate script given up on");

	ok(TEST_BACKEND_PIPE_UART);
	expect_line(TEST_BACKEND_PIPE_UART, MODEM_CELLULAR_TEST_INIT_CMD);
}

/* Without a reset or power key, recovery takes a modem left in CMUX mode back to AT mode
 * before booting it again
 */
ZTEST(modem_cellular_v2_core, test_recovery_without_gpios_disconnects_cmux)
{
	modem_restart(modem_no_power);
	advance_to(modem_no_power, BOOT_AT_READY);

	test_backend_pipe_disconnect(TEST_BACKEND_PIPE_DLCI1);
	expect_line(TEST_BACKEND_PIPE_UART, MODEM_CELLULAR_TEST_SET_BAUDRATE_CMD);
	zassert_equal(1, test_backend_cmux_disconnects(), "CMUX not disconnected");
	ok(TEST_BACKEND_PIPE_UART);
	expect_line(TEST_BACKEND_PIPE_UART, MODEM_CELLULAR_TEST_INIT_CMD);
}

/* A fault after the CMUX connects does not reset the recovery attempts */
ZTEST(modem_cellular_v2_core, test_recovery_spent_after_cmux)
{
	modem_restart(modem_no_dlci_setup);

	for (int i = 0; i <= CONFIG_MODEM_CELLULAR_MAX_RECOVERIES; i++) {
		advance_to(modem_no_dlci_setup, BOOT_SIM);
		test_backend_pipe_disconnect(TEST_BACKEND_PIPE_DLCI1);
	}

	/* Spent, so powered down rather than retried */
	expect_state(modem_no_dlci_setup, TEST_BACKEND_STATE_OFF);
	expect_no_line(K_MSEC(CONFIG_MODEM_CELLULAR_RECOVERY_BACKOFF_MS *
			      (CONFIG_MODEM_CELLULAR_MAX_RECOVERIES + 1)));
}

static struct {
	const struct gpio_dt_spec *spec;
	struct gpio_callback cb;
	int last;
	atomic_t presses;
} power_key;

static void power_key_handler(const struct device *port, struct gpio_callback *cb,
			      gpio_port_pins_t pins)
{
	int value = gpio_emul_output_get_dt(power_key.spec);

	ARG_UNUSED(port);
	ARG_UNUSED(cb);
	ARG_UNUSED(pins);

	if ((value == 1) && (power_key.last == 0)) {
		atomic_inc(&power_key.presses);
	}
	power_key.last = value;
}

/* Count the presses of the power key of @p dev from now on */
static void power_key_monitor_start(const struct device *dev)
{
	power_key.spec = test_backend_power_gpio(dev);
	power_key.last = gpio_emul_output_get_dt(power_key.spec);
	atomic_clear(&power_key.presses);
	gpio_init_callback(&power_key.cb, power_key_handler, BIT(power_key.spec->pin));
	zassert_ok(gpio_add_callback_dt(power_key.spec, &power_key.cb));
}

static atomic_val_t power_key_monitor_stop(void)
{
	(void)gpio_remove_callback_dt(power_key.spec, &power_key.cb);
	return atomic_get(&power_key.presses);
}

/* A modem that never reached CMUX is off, so recovery presses the power key once */
ZTEST(modem_cellular_v2_core, test_recovery_powers_on_stopped_modem)
{
	modem_restart(modem);
	advance_to(modem, BOOT_RECOVERY);
	power_key_monitor_start(modem);

	expect_line(TEST_BACKEND_PIPE_UART, MODEM_CELLULAR_TEST_SET_BAUDRATE_CMD);
	zassert_equal(1, power_key_monitor_stop(), "power key not pressed once");
}

/* A fault after the CMUX connects leaves the modem running, so recovery turns it off first */
ZTEST(modem_cellular_v2_core, test_recovery_power_cycles_running_modem)
{
	modem_restart(modem_no_dlci_setup);
	advance_to(modem_no_dlci_setup, BOOT_SIM);
	power_key_monitor_start(modem_no_dlci_setup);

	test_backend_pipe_disconnect(TEST_BACKEND_PIPE_DLCI1);
	expect_line(TEST_BACKEND_PIPE_UART, MODEM_CELLULAR_TEST_SET_BAUDRATE_CMD);
	zassert_equal(2, power_key_monitor_stop(), "power key not pressed twice");
}

/* Already suspended, so a second suspend returns without touching the modem */
ZTEST(modem_cellular_v2_core, test_suspend_when_idle)
{
	modem_restart(modem);
	advance_to(modem, BOOT_AT_READY);
	suspend_and_shutdown(modem);

	start_suspend(modem);
	finish_suspend(modem);
	expect_no_line(K_MSEC(100));
}

/* Software shutdown failed, fall back to the power key */
ZTEST(modem_cellular_v2_core, test_shutdown_script_failure)
{
	modem_restart(modem_slow);
	advance_to(modem_slow, BOOT_AT_READY);

	start_suspend(modem_slow);
	expect_line(TEST_BACKEND_PIPE_UART, MODEM_CELLULAR_TEST_SHUTDOWN_CMD);
	respond_error(TEST_BACKEND_PIPE_UART);
	expect_gpio(test_backend_power_gpio(modem_slow), 1);
	expect_gpio(test_backend_power_gpio(modem_slow), 0);
	finish_suspend(modem_slow);
	expect_no_line(K_MSEC(100));
}

/* Without a power key a failed shutdown script leaves the modem as it is */
ZTEST(modem_cellular_v2_core, test_shutdown_without_power_key)
{
	modem_restart(modem_no_power);
	advance_to(modem_no_power, BOOT_AT_READY);

	start_suspend(modem_no_power);
	expect_line(TEST_BACKEND_PIPE_UART, MODEM_CELLULAR_TEST_SHUTDOWN_CMD);
	respond_error(TEST_BACKEND_PIPE_UART);
	finish_suspend(modem_no_power);
	expect_no_line(K_MSEC(100));
}

/* Without a shutdown script the modem is powered down with the power key alone */
ZTEST(modem_cellular_v2_core, test_no_shutdown_script)
{
	modem_restart(modem_no_shutdown);
	advance_to(modem_no_shutdown, BOOT_AT_READY);

	start_suspend(modem_no_shutdown);
	finish_suspend(modem_no_shutdown);
	expect_no_line(K_MSEC(100));
}

ZTEST_SUITE(modem_cellular_v2_core, NULL, modem_test_setup, modem_test_before, modem_test_after,
	    NULL);
```

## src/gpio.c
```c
/*
 * Copyright (c) 2026 Embeint Inc
 *
 * SPDX-License-Identifier: Apache-2.0
 */

#include "test_helpers.h"

#include <zephyr/device.h>
#include <zephyr/drivers/gpio/gpio_emul.h>
#include <zephyr/drivers/modem/modem_cellular.h>
#include <modem_cellular_test.h>
#include <zephyr/ztest.h>

#define AUTOSTART_STARTUP_TIME_MS DT_PROP(DT_NODELABEL(modem_autostart), startup_time_ms)

static const struct device *const modem_hold = DEVICE_DT_GET(DT_NODELABEL(modem_hold));
static const struct device *const modem_resume = DEVICE_DT_GET(DT_NODELABEL(modem_resume));
static const struct device *const modem_recovery = DEVICE_DT_GET(DT_NODELABEL(modem_recovery));
static const struct device *const modem_autostart =
	DEVICE_DT_GET(DT_NODELABEL(modem_autostart));
static const struct device *const modem_status = DEVICE_DT_GET(DT_NODELABEL(modem_status));

static const struct gpio_dt_spec status_gpio =
	GPIO_DT_SPEC_GET(DT_NODELABEL(modem_status), mdm_status_gpios);

enum gpio_role {
	GPIO_ROLE_POWER,
	GPIO_ROLE_RESET,
};

/* A level change on a monitored pin, and the state of the link when it happened */
struct gpio_edge {
	enum gpio_role role;
	int value;
	enum test_backend_state state;
};

K_MSGQ_DEFINE(gpio_edges, sizeof(struct gpio_edge), 16, 4);

static struct {
	const struct device *dev;
	struct gpio_callback cb;
	int last[2];
	bool overflow;
} monitor;

static const char *const gpio_role_names[] = {
	[GPIO_ROLE_POWER] = "power",
	[GPIO_ROLE_RESET] = "reset",
};

static void gpio_monitor_record(enum gpio_role role, const struct gpio_dt_spec *spec)
{
	struct gpio_edge edge = {
		.role = role,
		.value = gpio_emul_output_get_dt(spec),
		.state = test_backend_state(monitor.dev),
	};

	if (edge.value == monitor.last[role]) {
		return;
	}
	monitor.last[role] = edge.value;
	/* Runs on the driver's thread, so leave asserting to the test thread */
	if (k_msgq_put(&gpio_edges, &edge, K_NO_WAIT) != 0) {
		monitor.overflow = true;
	}
}

/* The emulated GPIO controller fires callbacks synchronously on output changes, so every
 * level the driver drives is seen, however short the pulse.
 */
static void gpio_monitor_handler(const struct device *port, struct gpio_callback *cb,
				 gpio_port_pins_t pins)
{
	ARG_UNUSED(port);
	ARG_UNUSED(cb);
	ARG_UNUSED(pins);

	gpio_monitor_record(GPIO_ROLE_POWER, test_backend_power_gpio(monitor.dev));
	gpio_monitor_record(GPIO_ROLE_RESET, test_backend_reset_gpio(monitor.dev));
}

static void gpio_monitor_start(const struct device *dev)
{
	const struct gpio_dt_spec *power_gpio = test_backend_power_gpio(dev);
	const struct gpio_dt_spec *reset_gpio = test_backend_reset_gpio(dev);

	/* Start every test from released lines so the first recorded edge is the driver's */
	zassert_ok(gpio_pin_configure_dt(power_gpio, GPIO_OUTPUT_INACTIVE));
	zassert_ok(gpio_pin_configure_dt(reset_gpio, GPIO_OUTPUT_INACTIVE));

	monitor.dev = dev;
	monitor.last[GPIO_ROLE_POWER] = 0;
	monitor.last[GPIO_ROLE_RESET] = 0;
	monitor.overflow = false;
	k_msgq_purge(&gpio_edges);

	gpio_init_callback(&monitor.cb, gpio_monitor_handler,
			   BIT(power_gpio->pin) | BIT(reset_gpio->pin));
	zassert_ok(gpio_add_callback_dt(reset_gpio, &monitor.cb));
}

static void gpio_monitor_stop(void)
{
	if (monitor.dev == NULL) {
		return;
	}

	(void)gpio_remove_callback_dt(test_backend_reset_gpio(monitor.dev), &monitor.cb);
	monitor.dev = NULL;
}

/* Wait for the next edge, which must be @p role going to @p value in @p state */
static void expect_edge(enum gpio_role role, int value, enum test_backend_state state)
{
	struct gpio_edge edge;

	zassert_false(monitor.overflow, "GPIO edge queue overflowed");
	zassert_ok(k_msgq_get(&gpio_edges, &edge, K_SECONDS(1)), "timed out waiting for %s=%d",
		   gpio_role_names[role], value);
	zassert_equal(role, edge.role, "%s went to %d, expected %s=%d", gpio_role_names[edge.role],
		      edge.value, gpio_role_names[role], value);
	zassert_equal(value, edge.value, "%s went to %d, expected %d", gpio_role_names[role],
		      edge.value, value);
	zassert_equal(state, edge.state, "%s went to %d in state %d, expected state %d",
		      gpio_role_names[role], value, edge.state, state);
}

/* Expect @p role to be asserted and released again, both in @p state */
static void expect_pulse(enum gpio_role role, enum test_backend_state state)
{
	expect_edge(role, 1, state);
	expect_edge(role, 0, state);
}

/* Assert that neither pin changed since the last expected edge */
static void expect_no_edge(void)
{
	struct gpio_edge edge;

	zassert_false(monitor.overflow, "GPIO edge queue overflowed");
	if (k_msgq_get(&gpio_edges, &edge, K_NO_WAIT) == 0) {
		zassert_unreachable("unexpected %s=%d in state %d", gpio_role_names[edge.role],
				    edge.value, edge.state);
	}
}

static int64_t boot_modem(const struct device *dev)
{
	int64_t start;

	modem_reset_state(dev);
	gpio_monitor_start(dev);

	start = k_uptime_get();
	zassert_ok(modem_cellular_init(dev), "failed to reinitialize %s", dev->name);
	return start;
}

ZTEST(modem_cellular_gpio, test_hold_on_suspend)
{
	boot_modem(modem_hold);

	/* Held through init, released before the power key and the UART */
	expect_edge(GPIO_ROLE_RESET, 1, TEST_BACKEND_STATE_OFF);
	expect_edge(GPIO_ROLE_RESET, 0, TEST_BACKEND_STATE_OFF);
	expect_pulse(GPIO_ROLE_POWER, TEST_BACKEND_STATE_OFF);
	expect_line(TEST_BACKEND_PIPE_UART, MODEM_CELLULAR_TEST_SET_BAUDRATE_CMD);
	expect_no_edge();

	/* Reasserted on suspend */
	zassert_ok(modem_cellular_pm_action(modem_hold, PM_DEVICE_ACTION_SUSPEND),
		   "suspend failed");
	expect_edge(GPIO_ROLE_RESET, 1, TEST_BACKEND_STATE_AT);
	expect_no_edge();

	/* Released again on resume, before the power key and the UART */
	zassert_ok(modem_cellular_pm_action(modem_hold, PM_DEVICE_ACTION_RESUME), "resume failed");
	expect_edge(GPIO_ROLE_RESET, 0, TEST_BACKEND_STATE_OFF);
	expect_pulse(GPIO_ROLE_POWER, TEST_BACKEND_STATE_OFF);
	expect_line(TEST_BACKEND_PIPE_UART, MODEM_CELLULAR_TEST_SET_BAUDRATE_CMD);
	expect_no_edge();
}

ZTEST(modem_cellular_gpio, test_toggle_on_resume)
{
	boot_modem(modem_resume);

	expect_pulse(GPIO_ROLE_RESET, TEST_BACKEND_STATE_OFF);
	expect_pulse(GPIO_ROLE_POWER, TEST_BACKEND_STATE_OFF);
	expect_line(TEST_BACKEND_PIPE_UART, MODEM_CELLULAR_TEST_SET_BAUDRATE_CMD);
	expect_no_edge();

	/* Untouched on suspend, which powers the modem off */
	zassert_ok(modem_cellular_pm_action(modem_resume, PM_DEVICE_ACTION_SUSPEND),
		   "suspend failed");
	expect_pulse(GPIO_ROLE_POWER, TEST_BACKEND_STATE_OFF);
	expect_no_edge();

	/* Pulsed again on resume, before the power key and the UART */
	zassert_ok(modem_cellular_pm_action(modem_resume, PM_DEVICE_ACTION_RESUME),
		   "resume failed");
	expect_pulse(GPIO_ROLE_RESET, TEST_BACKEND_STATE_OFF);
	expect_pulse(GPIO_ROLE_POWER, TEST_BACKEND_STATE_OFF);
	expect_line(TEST_BACKEND_PIPE_UART, MODEM_CELLULAR_TEST_SET_BAUDRATE_CMD);
	expect_no_edge();
}

ZTEST(modem_cellular_gpio, test_toggle_on_recovery)
{
	boot_modem(modem_recovery);

	/* Untouched on boot */
	expect_pulse(GPIO_ROLE_POWER, TEST_BACKEND_STATE_OFF);
	expect_line(TEST_BACKEND_PIPE_UART, MODEM_CELLULAR_TEST_SET_BAUDRATE_CMD);
	expect_no_edge();
	ok(TEST_BACKEND_PIPE_UART);

	/* Fail the init script to push the state machine into recovery */
	expect_line(TEST_BACKEND_PIPE_UART, MODEM_CELLULAR_TEST_INIT_CMD);
	respond_error(TEST_BACKEND_PIPE_UART);

	expect_pulse(GPIO_ROLE_RESET, TEST_BACKEND_STATE_AT);
	expect_pulse(GPIO_ROLE_POWER, TEST_BACKEND_STATE_AT);
	expect_line(TEST_BACKEND_PIPE_UART, MODEM_CELLULAR_TEST_SET_BAUDRATE_CMD);
	expect_no_edge();
}

ZTEST(modem_cellular_gpio, test_autostarts_ready_message)
{
	struct test_backend_line line;
	int64_t start = boot_modem(modem_autostart);

	/* No AT commands until the modem reports it is ready */
	zassert_false(test_backend_wait_for_line(&line, K_MSEC(100)), "'%s' sent before ready",
		      line.data);
	zassert_equal(TEST_BACKEND_STATE_AT, test_backend_state(modem_autostart),
		      "boot stopped in state %d", test_backend_state(modem_autostart));
	test_backend_respond(TEST_BACKEND_PIPE_UART, "Ready\r");

	expect_line(TEST_BACKEND_PIPE_UART, MODEM_CELLULAR_TEST_SET_BAUDRATE_CMD);
	zassert_true(k_uptime_delta(&start) < AUTOSTART_STARTUP_TIME_MS,
		     "ready message did not cut the startup wait short");
	expect_no_edge();
}

ZTEST(modem_cellular_gpio, test_autostarts_ready_timeout)
{
	int64_t start = boot_modem(modem_autostart);
	int64_t elapsed;

	/* Without a ready message the full startup time elapses before AT commands */
	expect_line(TEST_BACKEND_PIPE_UART, MODEM_CELLULAR_TEST_SET_BAUDRATE_CMD);
	elapsed = k_uptime_delta(&start);
	zassert_true(elapsed >= AUTOSTART_STARTUP_TIME_MS,
		     "AT commands sent %lld ms after boot, before startup time elapsed",
		     (long long)elapsed);

	/* Autostarting modems go straight to waiting for the modem to come up */
	expect_no_edge();
}

static void set_modem_status(int value)
{
	zassert_ok(gpio_pin_configure_dt(&status_gpio, GPIO_INPUT));
	zassert_ok(gpio_emul_input_set_dt(&status_gpio, value));
}

ZTEST(modem_cellular_gpio, test_status_unpowered)
{
	set_modem_status(0);
	boot_modem(modem_status);

	expect_pulse(GPIO_ROLE_POWER, TEST_BACKEND_STATE_OFF);
	expect_line(TEST_BACKEND_PIPE_UART, MODEM_CELLULAR_TEST_SET_BAUDRATE_CMD);
	expect_no_edge();
}

ZTEST(modem_cellular_gpio, test_status_powered)
{
	set_modem_status(1);
	boot_modem(modem_status);

	/* Pulsing the power key would turn the running modem off */
	advance_to(modem_status, BOOT_CMUX_CONNECTED);
	expect_no_edge();
}

ZTEST(modem_cellular_gpio, test_status_powered_unresponsive)
{
	int64_t start;

	set_modem_status(1);
	boot_modem(modem_status);

	advance_to(modem_status, BOOT_INIT);
	expect_no_edge();

	/* The status line was wrong, so power the modem on without the recovery backoff */
	start = k_uptime_get();
	respond_error(TEST_BACKEND_PIPE_UART);
	expect_edge(GPIO_ROLE_POWER, 1, TEST_BACKEND_STATE_AT);
	zassert_true(k_uptime_delta(&start) < CONFIG_MODEM_CELLULAR_RECOVERY_BACKOFF_MS,
		     "recovery was entered");
	expect_edge(GPIO_ROLE_POWER, 0, TEST_BACKEND_STATE_AT);
	expect_line(TEST_BACKEND_PIPE_UART, MODEM_CELLULAR_TEST_SET_BAUDRATE_CMD);
	zassert_equal(modem_power_up_baudrate(modem_status), uart_baudrate(modem_status),
		      "UART baudrate was not restored on power up");
	expect_no_edge();
}

/* A suspend during the init script powers the modem off, so the resume powers it on from the
 * original baudrate
 */
ZTEST(modem_cellular_gpio, test_status_suspend_from_init)
{
	set_modem_status(1);
	boot_modem(modem_status);
	advance_to(modem_status, BOOT_INIT);

	start_suspend(modem_status);
	expect_pulse(GPIO_ROLE_POWER, TEST_BACKEND_STATE_OFF);
	set_modem_status(0);
	finish_suspend(modem_status);
	expect_no_edge();

	zassert_ok(modem_cellular_pm_action(modem_status, PM_DEVICE_ACTION_RESUME));
	expect_pulse(GPIO_ROLE_POWER, TEST_BACKEND_STATE_OFF);
	expect_line(TEST_BACKEND_PIPE_UART, MODEM_CELLULAR_TEST_SET_BAUDRATE_CMD);
	zassert_equal(modem_power_up_baudrate(modem_status), uart_baudrate(modem_status),
		      "UART baudrate was not restored on power up");
	expect_no_edge();
}

/* A modem that the status GPIO shows has turned off is not turned back on by the power key */
ZTEST(modem_cellular_gpio, test_status_shutdown_script_failure_unpowered)
{
	set_modem_status(1);
	boot_modem(modem_status);
	advance_to(modem_status, BOOT_DLCI1_SETUP);

	start_suspend(modem_status);
	expect_line(TEST_BACKEND_PIPE_UART, MODEM_CELLULAR_TEST_SHUTDOWN_CMD);
	set_modem_status(0);
	respond_error(TEST_BACKEND_PIPE_UART);
	finish_suspend(modem_status);
	expect_no_edge();
}

static void gpio_after(void *fixture)
{
	modem_test_after(fixture);
	gpio_monitor_stop();
}

ZTEST_SUITE(modem_cellular_gpio, NULL, modem_test_setup, modem_test_before, gpio_after, NULL);
```
